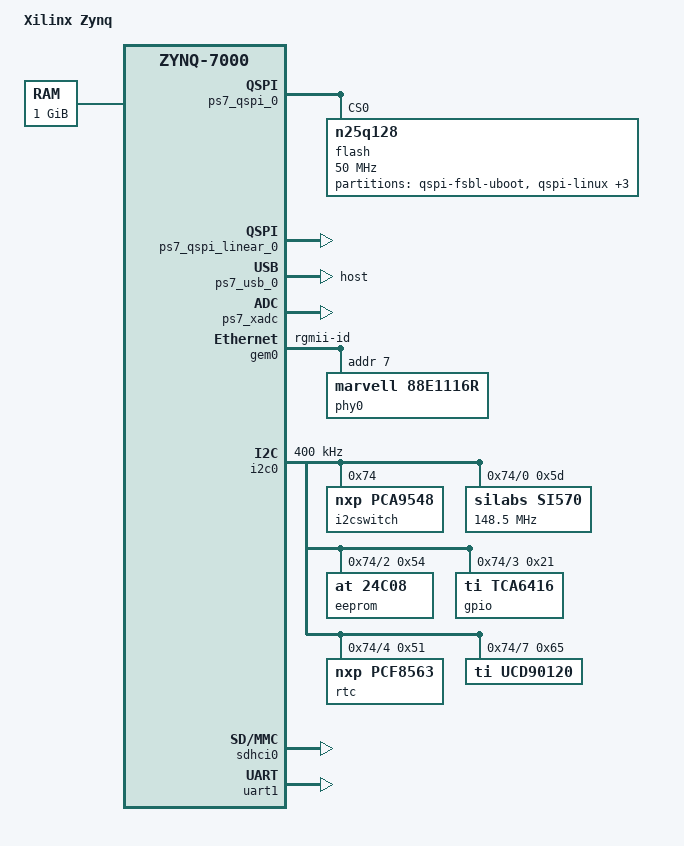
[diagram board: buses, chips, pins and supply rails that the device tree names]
/*
 * Device Tree Generator version: 1.1
 *
 * (C) Copyright 2007-2013 Xilinx, Inc.
 * (C) Copyright 2007-2013 Michal Simek
 * (C) Copyright 2007-2012 PetaLogix Qld Pty Ltd
 *
 * Michal SIMEK <monstr@monstr.eu>
 *
 * CAUTION: This file is automatically generated by libgen.
 * Version: Xilinx EDK 14.5 EDK_P.58f
 *
 */
/dts-v1/;
/include/ "zynq-7000.dtsi"

/ {
	compatible = "xlnx,zynq-zc706", "xlnx,zynq-7000";
	model = "Xilinx Zynq";

	aliases {
		ethernet0 = &gem0;
		i2c0 = &i2c0;
		serial0 = &uart1;
		spi0 = &ps7_qspi_0;
	};

	chosen {
		bootargs = "console=ttyPS0,115200 root=/dev/ram rw earlyprintk";
		linux,stdout-path = "/amba/serial@e0001000";
	};

	memory@0 {
		device_type = "memory";
		reg = <0x0 0x40000000>;
	};

	amba {
		ps7_afi_0: ps7-afi@f8008000 {
			compatible = "xlnx,ps7-afi-1.00.a";
			reg = <0xf8008000 0x1000>;
		} ;
		ps7_afi_1: ps7-afi@f8009000 {
			compatible = "xlnx,ps7-afi-1.00.a";
			reg = <0xf8009000 0x1000>;
		} ;
		ps7_afi_2: ps7-afi@f800a000 {
			compatible = "xlnx,ps7-afi-1.00.a";
			reg = <0xf800a000 0x1000>;
		} ;
		ps7_afi_3: ps7-afi@f800b000 {
			compatible = "xlnx,ps7-afi-1.00.a";
			reg = <0xf800b000 0x1000>;
		} ;
		ps7_ddrc_0: ps7-ddrc@f8006000 {
			compatible = "xlnx,zynq-ddrc-1.0";
			reg = <0xf8006000 0x1000>;
			xlnx,has-ecc = <0x0>;
		} ;
		ps7_dev_cfg_0: ps7-dev-cfg@f8007000 {
			clock-names = "ref_clk", "fclk0", "fclk1", "fclk2", "fclk3";
			clocks = <&clkc 12>, <&clkc 15>, <&clkc 16>, <&clkc 17>, <&clkc 18>;
			compatible = "xlnx,zynq-devcfg-1.0";
			interrupt-parent = <&intc>;
			interrupts = <0 8 4>;
			reg = <0xf8007000 0x100>;
		} ;
		ps7_dma_s: ps7-dma@f8003000 {
			#dma-cells = <1>;
			#dma-channels = <8>;
			#dma-requests = <4>;
			clock-names = "apb_pclk";
			clocks = <&clkc 27>;
			compatible = "arm,primecell", "arm,pl330";
			interrupt-names = "abort", "dma0", "dma1", "dma2", "dma3",
				"dma4", "dma5", "dma6", "dma7";
			interrupt-parent = <&intc>;
			interrupts = <0 13 4>, <0 14 4>, <0 15 4>, <0 16 4>, <0 17 4>, <0 40 4>, <0 41 4>, <0 42 4>, <0 43 4>;
			reg = <0xf8003000 0x1000>;
		} ;
		ps7_gpio_0: ps7-gpio@e000a000 {
			#gpio-cells = <2>;
			clocks = <&clkc 42>;
			compatible = "xlnx,zynq-gpio-1.0";
			emio-gpio-width = <64>;
			gpio-controller ;
			gpio-mask-high = <0x0>;
			gpio-mask-low = <0x0>;
			interrupt-parent = <&intc>;
			interrupts = <0 20 4>;
			reg = <0xe000a000 0x1000>;
		} ;
		ps7_iop_bus_config_0: ps7-iop-bus-config@e0200000 {
			compatible = "xlnx,ps7-iop-bus-config-1.00.a";
			reg = <0xe0200000 0x1000>;
		} ;
		ps7_ocmc_0: ps7-ocmc@f800c000 {
			compatible = "xlnx,zynq-ocmc-1.0";
			interrupt-parent = <&intc>;
			interrupts = <0 3 4>;
			reg = <0xf800c000 0x1000>;
		} ;
		ps7_qspi_0: ps7-qspi@e000d000 {
			clock-names = "ref_clk", "pclk";
			clocks = <&clkc 10>, <&clkc 43>;
			compatible = "xlnx,zynq-qspi-1.0";
			interrupt-parent = <&intc>;
			interrupts = <0 19 4>;
			is-dual = <1>;
			num-cs = <1>;
			reg = <0xe000d000 0x1000>;
			xlnx,fb-clk = <0x1>;
			xlnx,qspi-mode = <0x2>;
			#address-cells = <1>;
			#size-cells = <0>;
			flash@0 {
				compatible = "n25q128";
				reg = <0x0>;
				spi-tx-bus-width = <1>;
				spi-rx-bus-width = <4>;
				spi-max-frequency = <50000000>;
				#address-cells = <1>;
				#size-cells = <1>;
				partition@qspi-fsbl-uboot {
					label = "qspi-fsbl-uboot";
					reg = <0x0 0x100000>;
				};
				partition@qspi-linux {
					label = "qspi-linux";
					reg = <0x100000 0x500000>;
				};
				partition@qspi-device-tree {
					label = "qspi-device-tree";
					reg = <0x600000 0x20000>;
				};
				partition@qspi-rootfs {
					label = "qspi-rootfs";
					reg = <0x620000 0x5E0000>;
				};
				partition@qspi-bitstream {
					label = "qspi-bitstream";
					reg = <0xC00000 0x400000>;
				};
			};

		} ;
		ps7_qspi_linear_0: ps7-qspi-linear@fc000000 {
			clock-names = "ref_clk", "aper_clk";
			clocks = <&clkc 10>, <&clkc 43>;
			compatible = "xlnx,ps7-qspi-linear-1.00.a";
			reg = <0xfc000000 0x2000000>;
		} ;
		ps7_scuwdt_0: ps7-scuwdt@f8f00620 {
			clocks = <&clkc 4>;
			compatible = "xlnx,ps7-scuwdt-1.00.a";
			device_type = "watchdog";
			interrupt-parent = <&intc>;
			interrupts = <1 14 0x301>;
			reg = <0xf8f00620 0xe0>;
		} ;
		ps7_usb_0: ps7-usb@e0002000 {
			clocks = <&clkc 28>;
			compatible = "xlnx,ps7-usb-1.00.a", "xlnx,zynq-usb-1.00.a";
			dr_mode = "host";
			interrupt-parent = <&intc>;
			interrupts = <0 21 4>;
			phy_type = "ulpi";
			reg = <0xe0002000 0x1000>;
			usb-reset = <&ps7_gpio_0 7 0>;
		} ;
		ps7_wdt_0: ps7-wdt@f8005000 {
			clocks = <&clkc 45>;
			compatible = "xlnx,zynq-wdt-r1p2";
			device_type = "watchdog";
			interrupt-parent = <&intc>;
			interrupts = <0 9 1>;
			reg = <0xf8005000 0x1000>;
			reset = <0>;
			timeout-sec = <10>;
		} ;
		ps7_xadc: ps7-xadc@f8007100 {
			clocks = <&clkc 12>;
			compatible = "xlnx,zynq-xadc-1.00.a";
			interrupt-parent = <&intc>;
			interrupts = <0 7 4>;
			reg = <0xf8007100 0x20>;
		} ;
	};
};

&gem0 {
	status = "okay";
	phy-mode = "rgmii-id";

	phy0: phy@7 {
		compatible = "marvell,88e1116r";
		reg = <7>;
	};
};

&i2c0 {
	status = "okay";
	clock-frequency = <400000>;

	i2cswitch@74 {
		compatible = "nxp,pca9548";
		#address-cells = <1>;
		#size-cells = <0>;
		reg = <0x74>;

		i2c@0 {
			#address-cells = <1>;
			#size-cells = <0>;
			reg = <0>;
			si570: clock-generator@5d {
				#clock-cells = <0>;
				compatible = "silabs,si570";
				temperature-stability = <50>;
				reg = <0x5d>;
				factory-fout = <156250000>;
				clock-frequency = <148500000>;
			};
		};

		i2c@2 {
			#address-cells = <1>;
			#size-cells = <0>;
			reg = <2>;
			eeprom@54 {
				compatible = "at,24c08";
				reg = <0x54>;
			};
		};

		i2c@3 {
			#address-cells = <1>;
			#size-cells = <0>;
			reg = <3>;
			gpio@21 {
				compatible = "ti,tca6416";
				reg = <0x21>;
				gpio-controller;
				#gpio-cells = <2>;
			};
		};

		i2c@4 {
			#address-cells = <1>;
			#size-cells = <0>;
			reg = <4>;
			rtc@51 {
				compatible = "nxp,pcf8563";
				reg = <0x51>;
			};
		};

		i2c@7 {
			#address-cells = <1>;
			#size-cells = <0>;
			reg = <7>;
			ucd90120@65 {
				compatible = "ti,ucd90120";
				reg = <0x65>;
			};
		};
	};
};

&sdhci0 {
	status = "okay";
};

&uart1 {
	status = "okay";
};
